# PN74xxAU register map
File version: 2
CPU: CM0 r0p0, little endian, no MPU, no FPU, 2 interrupt priority bits
Registers are 32-bit, read-write, reset 0x0 unless marked. A register's access mark holds for its fields unless they carry their own. Offsets are from the block's base; [hi:lo] are bit positions.

## USB — Universal Serial Bus
Base 0x40028000
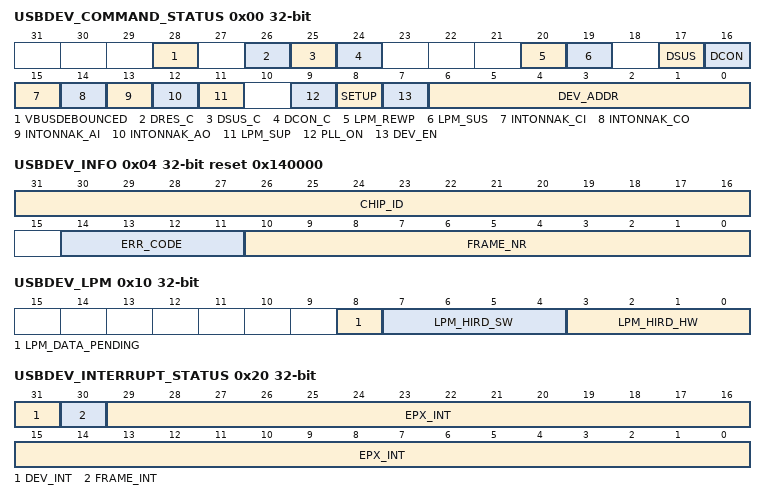
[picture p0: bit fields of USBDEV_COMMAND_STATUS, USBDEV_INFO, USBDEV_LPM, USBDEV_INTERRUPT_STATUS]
0x00 USBDEV_COMMAND_STATUS — USB Device Command/Status register
  [28] VBUSDEBOUNCED ro — This bit indicates if Vbus is detected or not. The bit raises immediately when Vbus becomes high. It drops to zero if Vbus is low for at least 3 ms. If this bit is high and the DCon bit is set, the HW will enable the pull-up resistor to signal a connect.
  [26] DRES_C — Device status - reset change Firmware must write a one to reset the bit
  [25] DSUS_C — Device status - suspend change Firmware must write a one to reset the bit
  [24] DCON_C — Device status - connect change Firmware must write a one to reset the bit
  [20] LPM_REWP ro — LPM Remote Wakeup Enabled by USB host
  [19] LPM_SUS — Device status - LPM Suspend
  [17] DSUS — Device status - suspend
  [16] DCON — Device status - connect
  [15] INTONNAK_CI — Interrupt on NAK for control IN EP
  [14] INTONNAK_CO — Interrupt on NAK for control OUT EP
  [13] INTONNAK_AI — Interrupt on NAK for interrupt and bulk IN EP
  [12] INTONNAK_AO — Interrupt on NAK for interrupt and bulk OUT EP
  [11] LPM_SUP — LPM Supported
  [9] PLL_ON — Always PLL Clock on
  [8] SETUP — SETUP token received SW must clear this bit by writing a one.
  [7] DEV_EN — USB device enable
  [6:0] DEV_ADDR — USB device address
0x04 USBDEV_INFO reset 0x140000 — USB Info
  [31:16] CHIP_ID ro — USB IP version number
  [14:11] ERR_CODE — The error code that last occurred
  [10:0] FRAME_NR ro — Frame number
0x08 USBDEV_EPLIST_START_ADDRESS — USB EP Command/Status List start address
  [31:8] EP_LIST — These are the programmable bits for firmware to indicate the start address of the USB EP Command/Status List
0x0C USBDEV_DATA_BUFFER_ADDRESS — USB Data buffer start address
  [31:22] DA_BUF — These are the programmable bits for firmware to indicate the buffer pointer page where all endpoint data buffers are located.
0x10 USBDEV_LPM — USB Link Power Management register
  [8] LPM_DATA_PENDING — As long as this bit is set to one and LPM supported bit is set to one, HW will return a NYET handshake on every LPM token it receives.
  [7:4] LPM_HIRD_SW — Host Initiated Resume Duration - SW This is the time duration required by the USB device system to come out of LPM initiated suspend after receiving the host initiated LPM resume.
  [3:0] LPM_HIRD_HW ro — Host Initiated Resume Duration - HW This is the HIRD value from the last received LPM token
0x14 USBDEV_ENDPOINT_SKIP — USB Endpoint skip
  [29:0] SKIP — Endpoint skip : Writing 1b to one of these bits, will indicate to HW that it must deactivate the buffer assigned to this endpoint and return control back to firmware.
0x18 USBDEV_EP_BUFFER_INUSE — USB Endpoint Buffer in use
  [29:0] BUF — Buffer in use : This register has one bit per physical endpoint. 0b : HW is accessing buffer 0 1b : HW is accessing buffer 1
0x1C USBDEV_EP_BUFFER_CONFIG — USB Endpoint Buffer Config
  [29:2] BUF_SB — Buffer usage - This register has one bit per physical endpoint 0b : Single buffer 1b : Double buffer
0x20 USBDEV_INTERRUPT_STATUS — USB interrupt status register
  [31] DEV_INT — Device status interrupt. This bit is set by HW when one of the device status change bits is set. Firmware can clear this bit by writing a one to it.
  [30] FRAME_INT — Frame interrupt. This bit is set to one every millisecond when the VbusDebounced bit and the DCON bit are set. This bit can be used by software when handling the isochronous endpoints. Firmware can clear this bit by writing a one to it.
  [29:0] EPX_INT — Interrupt status register bit for the corresponding endpoint. Firmware can clear this bit by writing a one to it.
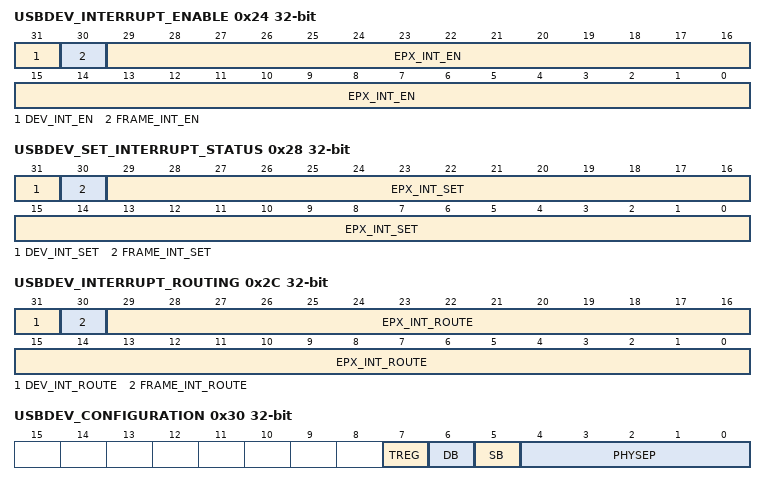
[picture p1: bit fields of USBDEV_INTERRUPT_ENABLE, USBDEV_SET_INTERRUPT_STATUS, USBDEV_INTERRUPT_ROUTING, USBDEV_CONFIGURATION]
0x24 USBDEV_INTERRUPT_ENABLE — USB interrupt enable register
  [31] DEV_INT_EN — If this bit is set and the corresponding USB interrupt status bit is set a HW interrupt is generated on the interrupt line indicated by the corresponding USB interrupt routing bit.
  [30] FRAME_INT_EN — If this bit is set and the corresponding USB interrupt status bit is set a HW interrupt is generated on the interrupt line indicated by the corresponding USB interrupt routing bit.
  [29:0] EPX_INT_EN — If this bit is set and the corresponding USB interrupt status bit is set a HW interrupt is generated on the interrupt line indicated by the corresponding USB interrupt routing bit.
0x28 USBDEV_SET_INTERRUPT_STATUS — USB set interrupt status register
  [31] DEV_INT_SET — If firmware writes a one to one of these bits, the corresponding USB interrupt status bit is set. When this register is read, the same value as the USB interrupt status register is returned.
  [30] FRAME_INT_SET — If firmware writes a one to one of these bits, the corresponding USB interrupt status bit is set. When this register is read, the same value as the USB interrupt status register is returned.
  [29:0] EPX_INT_SET — If firmware writes a one to one of these bits, the corresponding USB interrupt status bit is set. When this register is read, the same value as the USB interrupt status register is returned.
0x2C USBDEV_INTERRUPT_ROUTING — USB interrupt routing
  [31] DEV_INT_ROUTE — This bit determines to which HW interrupt line the interrupt is routed (0b = IRQ; 1b = FIQ)
  [30] FRAME_INT_ROUTE — This bit determines to which HW interrupt line the interrupt is routed (0b = IRQ; 1b = FIQ)
  [29:0] EPX_INT_ROUTE — This bit determines to which HW interrupt line the corresponding interrupt is routed (0b = IRQ; 1b = FIQ)
0x30 USBDEV_CONFIGURATION ro — USB Configuration
  [7] TREG — Toggle register available
  [6] DB — EP Double buffer supported (derived from VHDL generic C_DOUBLE_BUFFER_SUPPORTED)
  [5] SB — EP Single buffer supported (derived from VHDL generic C_SINGLE_BUFFER_SUPPORTED)
  [4:0] PHYSEP — Number of physical endpoints implemented in this design (excluding the default control endpoint 0) E.g. a value of 2 indicates that the design contains the default control endpoint plus one IN endpoint (EP1 - IN) and one OUT endpoint (EP1 - OUT)
0x34 USBDEV_ENDPOINT_TOGGLE ro — USB Endpoint toggle
  [29:0] TOGGLE — Endpoint data toggle
0x38 USBDEV_INTERNAL_PLL — USB Internal PLL
  [0] SEL_EXT_CLK — Select external crystal clock
